AUTOSAR XML (schema 00049)
standard types defined: boolean, float32, sint16, uint16, uint8, boolean_CompuMethod, boolean_DataConstr, float32_DataConstr, uint16_DataConstr, uint8_DataConstr
package /AUTOSAR_Platform/ImplementationDataTypes
  impl type sint16_const: category=VALUE, base-type=sint16, range raw -32768..32767, additional-native-type-qualifier=const  # SInt16 represents integers with a minimum value of -32768 and a maximum value of 32767. The order-relation on sint16 is: x < y if y - x is positive. sint16 has a lexical representation consisting of an optional sign followed by a finite-length sequence of decimal digits (#x30-#x39). If the sign is omitted, "+" is assumed. For example: -1, 0, -12678, +10000, 2500
package /ComponentTypes
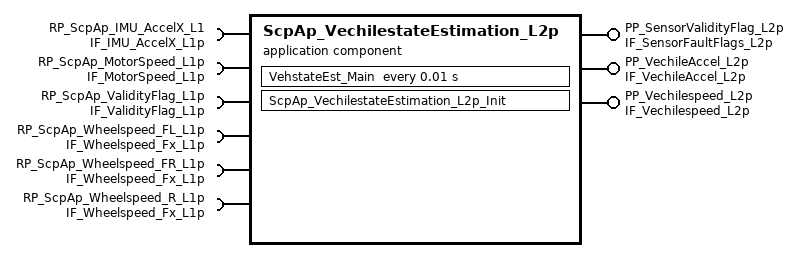
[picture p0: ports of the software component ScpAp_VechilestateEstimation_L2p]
  application sw component type ScpAp_VechilestateEstimation_L2p
    6 x require port:
      RP_ScpAp_IMU_AccelX_L1: nonqueued-receiver-com-spec{data-element=IF_IMU_AccelX_L1p, init-value=0}, required-interface=IF_IMU_AccelX_L1p
      RP_ScpAp_MotorSpeed_L1p: nonqueued-receiver-com-spec{data-element=IF_MotorSpeed_L1p, init-value=ComSpec8213ca7e_f94256d2655c1c70:0}, required-interface=IF_MotorSpeed_L1p
      RP_ScpAp_ValidityFlag_L1p: nonqueued-receiver-com-spec{data-element=IF_ValidityFlag_L1p, init-value={short-label=ComSpec645b8bda_6ebfdf5ca0105563, fields=[Motor_RPM_Valid_Flg:0, WSS_FR_Valid_Flg:0, WSS_FL_Valid_Flg:0, WSS_R_Valid_Flg:0, IMU_AccelX_Valid_Flg:0, SensorStuck_Valid_Flg:0]}}, required-interface=IF_ValidityFlag_L1p
      RP_ScpAp_Wheelspeed_FL_L1p: nonqueued-receiver-com-spec{data-element=IF_Wheelspeed_Fx_L1p, init-value=ComSpec047a1b6a_7c46f554c5c2f392:0}, required-interface=IF_Wheelspeed_Fx_L1p
      RP_ScpAp_Wheelspeed_FR_L1p: nonqueued-receiver-com-spec{data-element=IF_Wheelspeed_Fx_L1p, init-value=ComSpec52951305_1b96cb25478a113f:0}, required-interface=IF_Wheelspeed_Fx_L1p
      RP_ScpAp_Wheelspeed_R_L1p: nonqueued-receiver-com-spec{data-element=IF_Wheelspeed_Fx_L1p, init-value=ComSpecccb9cf87_4dbad64891ce6307:0}, required-interface=IF_Wheelspeed_Fx_L1p
    provide port PP_SensorValidityFlag_L2p: nonqueued-sender-com-spec{data-element=IF_SensorFaultFlags_L2p, init-value={short-label=ComSpec1c4adf9b_bdbaff7a7844ed70, fields=[MotorRPM_Fault:0, Accel_Fault:0, WSS_Fault:0, VechSpeedEst_Fault:0]}}, provided-interface=IF_SensorFaultFlags_L2p
    provide port PP_VechileAccel_L2p: nonqueued-sender-com-spec{data-element=IF_VechileAccel_L2p, init-value=0}, provided-interface=IF_VechileAccel_L2p
    provide port PP_Vechilespeed_L2p: nonqueued-sender-com-spec{data-element=IF_Vechilespeed_L2p, init-value=0}, provided-interface=IF_Vechilespeed_L2p
    behavior ScpAp_VechilestateEstimation_L2p_InternalBehavior: handle-termination-and-restart=NO-SUPPORT
      constant-memorys:
        5 x parameter data prototype, all with category=VALUE, sw-addr-method=CALIB, sw-calibration-access=READ-WRITE:
          Accel_Diff_Th: type=float64_const, init-value=Accel_Diff_Th:1
          Speed_Diff_Th: type=float64_const, init-value=Speed_Diff_Th:4
          Wheel_Diff_Th: type=float64_const, init-value=Wheel_Diff_Th:5
          W1: type=sint16_const, init-value=W1:0
          W2: type=sint16_const, init-value=W2:1
      static-memorys:
        18 x data, all with category=VALUE, sw-addr-method=ASW_Variable, sw-calibration-access=READ-ONLY:
          VehicleSpeed_L2_Prev: type=sint16
          ScpAp_VechilestateE_Valid_Wheel: type=float64
          ScpAp_Vechilestat_Valid_Wheel_R: type=float64
          ScpAp_Vechilesta_Valid_Wheel_FR: type=float64
          ScpAp_Vechilesta_Valid_Wheel_FL: type=float64
          ScpAp_V_VehicleAccel_from_speed: type=uint16
          ScpAp_Vechilest_VehicleAccel_L2: type=uint16
          ScpAp_Vechi_Cal_VehicleAccel_L2: type=uint16
          ScpAp_Vechilestat_WSS_x_L1p_Max: type=uint16
          ScpAp_Vechilestat_WSS_x_L1p_Min: type=uint16
          ScpAp_VehicleSpeed_Weighted_L2: type=sint16
          ScpAp_Vechilest_VehicleSpeed_L2: type=sint16
          ScpAp_VechilestateEst_Motor_Spd: type=sint16
          ScpAp_Vech_VhlSpd_Wgt_L2_Switch: type=boolean
          ScpAp_Vechilesta_MotorRPM_Fault: type=boolean
          ScpAp_VechilestateE_Accel_Fault: type=boolean
          ScpAp_VechilestateEst_WSS_Fault: type=boolean
          ScpAp_Vechile_VehSpeedEst_Fault: type=boolean
      timing event TMT_VehstateEst_Main: start-on-event=VehstateEst_Main, period=0.01
      runnable VehstateEst_Main: sw-addr-method=CODE
        data-receive-point-by-arguments:
          6 x access:
            IN_RP_ScpAp_IMU_AccelX_L1_IF_IMU_AccelX_L1p: accessed-variable=RP_ScpAp_IMU_AccelX_L1.IF_IMU_AccelX_L1p
            IN_RP_ScpAp_MotorSpeed_L1p_IF_MotorSpeed_L1p: accessed-variable=RP_ScpAp_MotorSpeed_L1p.IF_MotorSpeed_L1p
            IN_RP_ScpAp_ValidityFlag_L1p_IF_ValidityFlag_L1p: accessed-variable=RP_ScpAp_ValidityFlag_L1p.IF_ValidityFlag_L1p
            IN_RP_ScpAp_Wheelspeed_FL_L1p_IF_Wheelspeed_Fx_L1p: accessed-variable=RP_ScpAp_Wheelspeed_FL_L1p.IF_Wheelspeed_Fx_L1p
            IN_RP_ScpAp_Wheelspeed_FR_L1p_IF_Wheelspeed_Fx_L1p: accessed-variable=RP_ScpAp_Wheelspeed_FR_L1p.IF_Wheelspeed_Fx_L1p
            IN_RP_ScpAp_Wheelspeed_R_L1p_IF_Wheelspeed_Fx_L1p: accessed-variable=RP_ScpAp_Wheelspeed_R_L1p.IF_Wheelspeed_Fx_L1p
        data-send-points:
          access OUT_PP_SensorValidityFlag_L2p_IF_SensorFaultFlags_L2p: accessed-variable=PP_SensorValidityFlag_L2p.IF_SensorFaultFlags_L2p
          access OUT_PP_VechileAccel_L2p_IF_VechileAccel_L2p: accessed-variable=PP_VechileAccel_L2p.IF_VechileAccel_L2p
          access OUT_PP_Vechilespeed_L2p_IF_Vechilespeed_L2p: accessed-variable=PP_Vechilespeed_L2p.IF_Vechilespeed_L2p
      runnable ScpAp_VechilestateEstimation_L2p_Init: sw-addr-method=CODE
package /DataTypes
  impl type IF_SensorFaultFlgs_L2p_IDT: category=STRUCTURE
    4 x element, all with category=TYPE_REFERENCE, implementation-data-type=boolean:
      MotorRPM_Fault
      Accel_Fault
      WSS_Fault
      VechSpeedEst_Fault
  impl type IF_ValidityFlag_L1p_IDT: category=STRUCTURE
    6 x element, all with category=TYPE_REFERENCE, implementation-data-type=boolean:
      Motor_RPM_Valid_Flg
      WSS_FR_Valid_Flg
      WSS_FL_Valid_Flg
      WSS_R_Valid_Flg
      IMU_AccelX_Valid_Flg
      SensorStuck_Valid_Flg
package /PortInterfaces
  7 x sender receiver interface:
    IF_IMU_AccelX_L1p: invalidation-policy{data-element=IF_IMU_AccelX_L1p, handle-invalid=DONT-INVALIDATE}
      data IF_IMU_AccelX_L1p: category=VALUE, sw-calibration-access=READ-ONLY, type=float32
    IF_MotorSpeed_L1p: invalidation-policy{data-element=IF_MotorSpeed_L1p, handle-invalid=DONT-INVALIDATE}
      data IF_MotorSpeed_L1p: category=VALUE, sw-calibration-access=READ-ONLY, type=uint8
    IF_SensorFaultFlags_L2p: invalidation-policy{data-element=IF_SensorFaultFlags_L2p, handle-invalid=DONT-INVALIDATE}
      data IF_SensorFaultFlags_L2p: category=STRUCTURE, sw-calibration-access=READ-ONLY, type=IF_SensorFaultFlgs_L2p_IDT
    IF_ValidityFlag_L1p: invalidation-policy{data-element=IF_ValidityFlag_L1p, handle-invalid=DONT-INVALIDATE}
      data IF_ValidityFlag_L1p: category=STRUCTURE, sw-calibration-access=READ-ONLY, type=IF_ValidityFlag_L1p_IDT
    IF_VechileAccel_L2p: invalidation-policy{data-element=IF_VechileAccel_L2p, handle-invalid=DONT-INVALIDATE}
      data IF_VechileAccel_L2p: category=VALUE, sw-calibration-access=READ-ONLY, type=sint16
    IF_Vechilespeed_L2p: invalidation-policy{data-element=IF_Vechilespeed_L2p, handle-invalid=DONT-INVALIDATE}
      data IF_Vechilespeed_L2p: category=VALUE, sw-calibration-access=READ-ONLY, type=uint16
    IF_Wheelspeed_Fx_L1p: invalidation-policy{data-element=IF_Wheelspeed_Fx_L1p, handle-invalid=DONT-INVALIDATE}
      data IF_Wheelspeed_Fx_L1p: category=VALUE, sw-calibration-access=READ-ONLY, type=uint16
